# M0519AE_v1 register map
File version: 1.0
Registers are 32-bit, read-write, reset 0x0 unless marked. A register's access mark holds for its fields unless they carry their own. Offsets are from the block's base; [hi:lo] are bit positions; {n}, {i} and the like mark numbered series; 'fields as' and 'values as' point back to an identical list.

## EADC — EADC Register Map
Base 0x400E0000
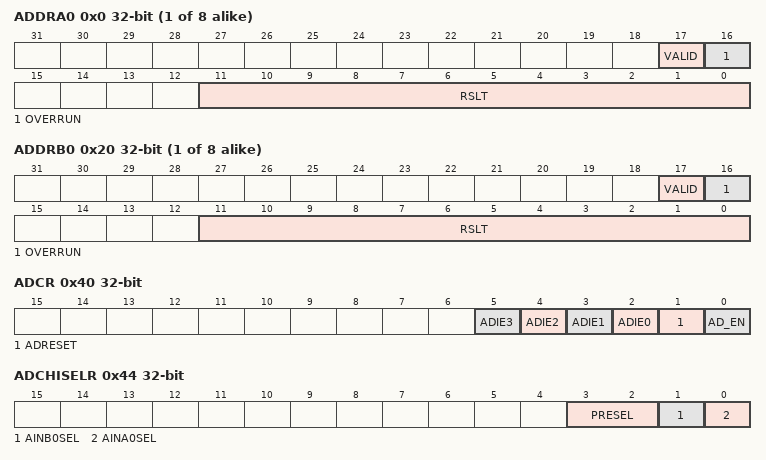
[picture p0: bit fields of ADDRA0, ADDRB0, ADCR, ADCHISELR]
{0x0+4i} ADDRA{i} ro (i=0..7) — A/D Data Register {i} for SAMPLEA{i}
  [17] VALID — Valid Flag. This bit is set to 1 when corresponding SAMPLE channel analog input conversion is completed and cleared by hardware after ADDR register is read.
    0=Data in RSLT[11:0] bits is not valid; 1=Data in RSLT[11:0] bits is valid
  [16] OVERRUN — over Run Flag
    0=Data in RSLT[11:0] is the recent conversion result; 1=Data in RSLT[11:0] is overwritten. If converted data in RSLT[11:0] has not been read before new conversion result is loaded to this register, OVERRUN is set to 1. It is cleared by hardware after ADDR register is read
  [11:0] RSLT — A/D Conversion Result. This field contains 12-bit conversion result.
{0x20+4i} ADDRB{i} ro (i=0..7) — A/D Data Register {i+8} for SAMPLEB{i}
  fields as ADDRA0
0x40 ADCR — A/D Control Register
  [n+2] ADIE{n} (n=0..3) — Specific SAMPLE A/D ADINT{n} Interrupt Enable Bit. The A/D converter generates a conversion end ADF{n} flag in ADSR1 register upon the end of specific SAMPLE A/D conversion. If ADIE{n} bit is set then conversion end interrupt request ADINT{n} is generated.
    0=Specific SAMPLE A/D ADINT{n} interrupt function Disabled; 1=Specific SAMPLE A/D ADINT{n} interrupt function Enabled
  [1] ADRESET — ADCA, ADCB A/D Converter Control Circuits Reset. Note: This bit remains 1 during ADC reset, when ADC reset end, the ADRESET bit is automatically cleared to 0.
    0=Writing 0 has no effect; 1=Writing 1 will cause ADC control circuits reset to initial state, but not change the ADC registers value
  [0] AD_EN — A/D Converter Enable Bit. Note: Before starting the A/D conversion function, this bit should be set to 1. Clear it to 0 to disable A/D converter analog circuit power consumption.
    0=A/D converter Disabled; 1=A/D converter Enabled
0x44 ADCHISELR — A/D Channel Input Sources Select Register
  [3:2] PRESEL — A/D Channel AINA[7] Analog Input Selection
    0=Analog Input Channel AINA7; 1=Band-gap (VBG) Analog Input; 2=VTEMP Internal Temperature Sensor Analog Input; 3=Analog ground
  [1] AINB0SEL — A/D Channel AINB[0] Analog Input Selection
    0=AINB[0] pin P7.0E/EADC1_CH0 is selected as the A/D AINB[0] input signal; 1=OP Amplifier 1 output is selected as the A/D AINB[0] input signal
  [0] AINA0SEL — A/D Channel AINA[0] Analog Input Selection
    0=AINA[0] pin P6.0/EADC0_CH0is selected as the ADC AINA[0] input signal; 1=OP Amplifier 0 output is selected as the ADC AINA[0] input signal
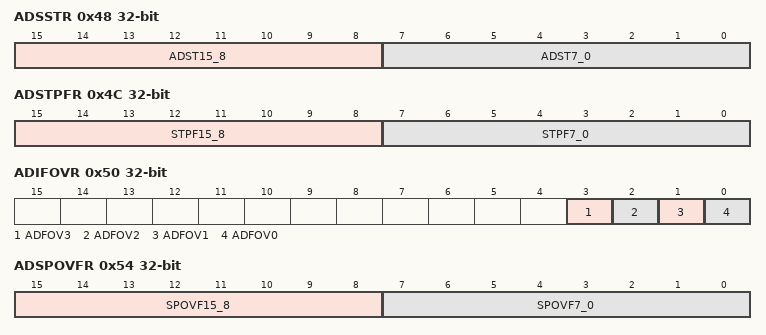
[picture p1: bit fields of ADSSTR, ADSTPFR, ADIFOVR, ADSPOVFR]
0x48 ADSSTR wo — A/D SAMPLE Software Start Register
  [15:8] ADST15_8 — A/D SAMPLEB7~0 Software Force to Start ADC Conversion Register
    0=No effect; 1=Cause an ADC conversion when the priority is given to SAMPLEB
  [7:0] ADST7_0 — A/D SAMPLEA7~0 Software Force to Start ADC Conversion Register
    0=No effect; 1=Cause an ADC conversion when the priority is given to SAMPLEA
0x4C ADSTPFR ro — A/D SAMPLE Start of Conversion Pending Flag Register
  [15:8] STPF15_8 — A/D SAMPLEB7~0 Start Conversion Pending Flag
    0=No pending conversion for SAMPLEB; 1=SAMPLEBn ADC start of conversion is pending
  [7:0] STPF7_0 — A/D SAMPLEA7~0 Start Conversion Pending Flag
    0=There is no pending conversion for SAMPLEA; 1=SAMPLEAn ADC start of conversion is pending
0x50 ADIFOVR — A/D ADINT3~0 Interrupt Flag over Run Register
  [3] ADFOV3 — A/D ADINT3 Interrupt Flag over Run Bit. Note: This bit is cleared by writing 1 to 1.
    0=ADINT3 interrupt flag is not over run; 1=ADINT3 interrupt pulse received when ADF3 is 1
  [2] ADFOV2 — A/D ADINT2 Interrupt Flag over Run Bit. Note: This bit is cleared by writing 1 to 1.
    0=ADINT2 interrupt flag is not over run; 1=ADINT2 interrupt flag is overwrite to 1
  [1] ADFOV1 — A/D ADINT1 Interrupt Flag over Run Bit. Note: This bit is cleared by writing 1 to 1.
    0=ADINT1 interrupt flag is not over run; 1=ADINT1 interrupt flag is overwrite to 1
  [0] ADFOV0 — A/D ADINT0 Interrupt Flag over Run Bit. Note: This bit is cleared by writing 1 to 1.
    0=ADINT0 interrupt flag is not over run; 1=ADINT0 interrupt flag is overwrite to 1
0x54 ADSPOVFR — A/D SAMPLE Start of Conversion over Run Flag Register
  [15:8] SPOVF15_8 — A/D SAMPLEB7~SAMPLEB0 Start Conversion Overrun Flag
    0=No SAMPLE event overrun; 1=Indicates new SAMPLEBn event is generated while an old one event is pending
  [7:0] SPOVF7_0 — A/D SAMPLEA7~SAMPLEA0 Start Conversion Overrun Flag
    0=No SAMPLE event overrun; 1=Indicates new SAMPLEAn event is generated while an old one event is pending
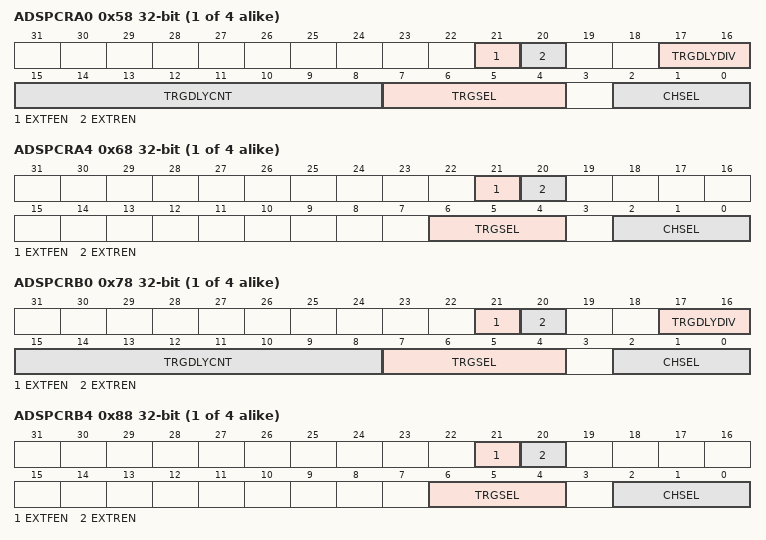
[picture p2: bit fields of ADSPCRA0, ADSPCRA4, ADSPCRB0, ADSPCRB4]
{0x58+4i} ADSPCRA{i} (i=0..3) — A/D SAMPLEA{i} Control Register
  [21] EXTFEN — A/D External Trigger Falling Edge Enable Bit
    0=Falling edge Disabled when A/D selects STADC as trigger source; 1=Falling edge Enabled when A/D selects STADC as trigger source
  [20] EXTREN — A/D External Trigger Rising Edge Enable Bit
    0=Rising edge Disabled when A/D selects STADC as trigger source; 1=Rising edge Enabled when A/D selects STADC as trigger source
  [17:16] TRGDLYDIV — A/D SAMPLE Start Conversion Trigger Delay Clock Divider Selection. Trigger delay clock frequency:
    0=ADC_CLK/1; 1=ADC_CLK/2; 2=ADC_CLK/4; 3=ADC_CLK/16
  [15:8] TRGDLYCNT — A/D SAMPLE Start Conversion Trigger Delay Time
  [7:4] TRGSEL — A/D SAMPLE Start Conversion Trigger Source Selection
    0=Disable hardware trigger; 1=External trigger from STADC pin input; 2=ADC ADINT0 interrupt EOC pulse trigger; 3=ADC ADINT1 interrupt EOC pulse trigger; {v}=Timer{v-4} overflow pulse trigger (v=4..7); 8=PWM00 trigger; 9=PWM02 trigger; 10=PWM04 trigger; 11=PWM10 trigger; 12=PWM12 trigger; 13=PWM14 trigger; 14=PWM20 trigger; 15=PWM21 trigger
  [2:0] CHSEL — A/D SAMPLEA,B Channel Selection
    {v}=AINx[{v}] (v=0..7)
{0x58+4i} ADSPCRA{i} (i=4..7) — A/D SAMPLEA{i} Control Register
  [21] EXTFEN — A/D External Trigger Falling Edge Enable Bit
    values as ADSPCRA0.EXTFEN
  [20] EXTREN — A/D External Trigger Rising Edge Enable Bit
    values as ADSPCRA0.EXTREN
  [6:4] TRGSEL — A/D SAMPLE Start Conversion Trigger Source Selection
    0=Disable hardware trigger; 1=External trigger from STADC pin input; 2=ADC ADINT0 interrupt EOC pulse trigger; 3=ADC ADINT1 interrupt EOC pulse trigger; {v}=Timer{v-4} overflow pulse trigger (v=4..7)
  [2:0] CHSEL — A/D SAMPLEA,B Channel Selection
    {v}=AINx[{v}] (v=0..7)
{0x78+4i} ADSPCRB{i} (i=0..3) — A/D SAMPLEB{i} Control Register
  fields as ADSPCRA0
{0x78+4i} ADSPCRB{i} (i=4..7) — A/D SAMPLEB{i} Control Register
  fields as ADSPCRA4
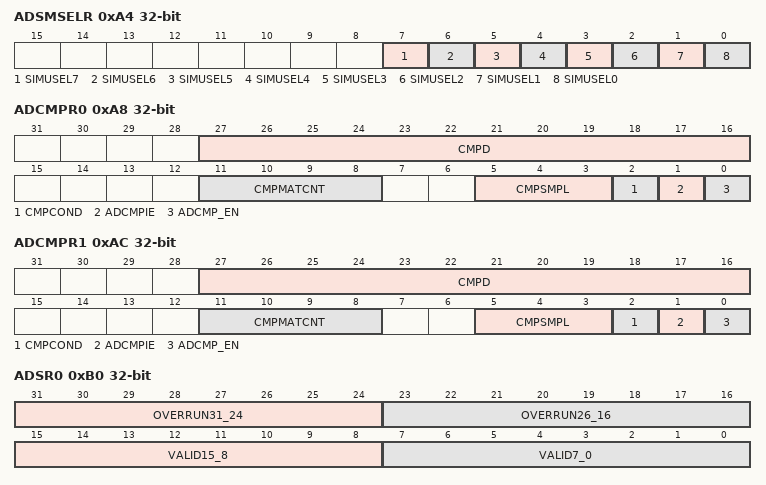
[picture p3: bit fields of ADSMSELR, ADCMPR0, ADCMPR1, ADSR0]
0xA4 ADSMSELR — A/D SAMPLE Simultaneous Mode Select Register
  [7] SIMUSEL7 — A/D SAMPLEA7, SAMPLEB7 Simultaneous Sampling Mode Selection
    0=SAMPLEA7, SAMPLEB7 are in single sampling mode, both SAMPLEA7 and SAMPLEB7's 3 bits of CHSEL define the ADC channels to be converted; 1=SAMPLEA7, SAMPLEB7 are in simultaneous sampling mode, Only SAMPLEA7 can trigger both the ADC conversions of SAMPLEA7 and SAMPLEB7, SAMPLEB7 trigger select TRGSEL is ignored. If SAMPLEA7's CHSEL = 1, SAMPLEB7's CHSEL = 3, the pair of channels are AINA[1], AINB[3], they will do the ADC conversion at the same time
  [6] SIMUSEL6 — A/D SAMPLEA6, SAMPLEB6 Simultaneous Sampling Mode Selection
    0=SAMPLEA6, SAMPLEB6 are in single sampling mode, both SAMPLEA6 and SAMPLEB6's 3 bits of CHSEL define the ADC channels to be converted; 1=SAMPLEA6, SAMPLEB6 are in simultaneous sampling mode, Only SAMPLEA6 can trigger both the ADC conversions of SAMPLEA6 and SAMPLEB6, SAMPLEB6 trigger select TRGSEL is ignored. If SAMPLEA6's CHSEL = 1, and SAMPLEB6's CHSEL = 3, the pair of channels are AINA[1], AINB[3], they will do the ADC conversion at the same time
  [5] SIMUSEL5 — A/D SAMPLEA5, SAMPLEB5 Simultaneous Sampling Mode Selection
    0=SAMPLEA5, SAMPLEB5 are in single sampling mode, both SAMPLEA5 and SAMPLEB5's 3 bits of CHSEL define the ADC channels to be converted; 1=SAMPLEA5, SAMPLEB5 are in simultaneous sampling mode, Only SAMPLEA5 can trigger both the ADC conversions of SAMPLEA5 and SAMPLEB5, SAMPLEB5 trigger select TRGSEL is ignored. If SAMPLEA5's CHSEL = 1, and SAMPLEB5's CHSEL = 3, the pair of channels are AINA[1], AINB[3], they will do the ADC conversion at the same time
  [4] SIMUSEL4 — A/D SAMPLEA4, SAMPLEB4 Simultaneous Sampling Mode Select Ion
    0=SAMPLEA4, SAMPLEB4 are in single sampling mode, both SAMPLEA4 and SAMPLEB4's 3 bits of CHSEL define the ADC channels to be converted; 1=SAMPLEA4, SAMPLEB4 are in simultaneous sampling mode, Only SAMPLEA4 can trigger both the ADC conversions of SAMPLEA4 and SAMPLEB4, SAMPLEB4 trigger select TRGSEL is ignored. If SAMPLEA4's CHSEL = 1, and SAMPLEB4's CHSEL = 3, the pair of channels are AINA[1], AINB[3], they will do the ADC conversion at the same time
  [3] SIMUSEL3 — A/D SAMPLEA3, SAMPLEB3 Simultaneous Sampling Mode Select Ion
    0=SAMPLEA3, SAMPLEB3 are in single sampling mode, both SAMPLEA3 and SAMPLEB3's 3 bits of CHSEL define the ADC channels to be converted; 1=SAMPLEA3, SAMPLEB3 are in simultaneous sampling mode, Only SAMPLEA3 can trigger both the ADC conversions of SAMPLEA3 and SAMPLEB3, SAMPLEB3 trigger select TRGSEL is ignored. If SAMPLEA3's CHSEL = 1, and SAMPLEB3's CHSEL = 3, the pair of channels are AINA[1], AINB[3], they will do the ADC conversion at the same time
  [2] SIMUSEL2 — A/D SAMPLEA2, SAMPLEB2 Simultaneous Sampling Mode Selection
    0=SAMPLEA2, SAMPLEB2 are in single sampling mode, both SAMPLEA2 and SAMPLEB2's 3 bits of CHSEL define the ADC channels to be converted; 1=SAMPLEA2, SAMPLEB2 are in simultaneous sampling mode, Only SAMPLEA2 can trigger both the ADC conversions of SAMPLEA2 and SAMPLEB2, SAMPLEB2 trigger select TRGSEL is ignored. If SAMPLEA2's CHSEL = 1, and SAMPLEB2's CHSEL = 3, the pair of channels are AINA[1], AINB[3], they will do the ADC conversion at the same time
  [1] SIMUSEL1 — A/D SAMPLEA1, SAMPLEB1 Simultaneous Sampling Mode Selection
    0=SAMPLEA1, SAMPLEB1 are in single sampling mode, both SAMPLEA1 and SAMPLEB1's 3 bits of CHSEL define the ADC channels to be converted; 1=SAMPLEA1, SAMPLEB1 are in simultaneous sampling mode, Only SAMPLEA1 can trigger both the ADC conversions of SAMPLEA1 and SAMPLEB1, SAMPLEB1 trigger select TRGSEL is ignored. If SAMPLEA1's CHSEL = 1, and SAMPLEB1's CHSEL = 3, the pair of channels are AINA[1], AINB[3], they will do the ADC conversion at the same time
  [0] SIMUSEL0 — A/D SAMPLEA0, SAMPLEB0 Simultaneous Sampling Mode Selection
    0=SAMPLEA0, SAMPLEB0 are in single sampling mode, both SAMPLEA0 and SAMPLEB0's 3 bits of CHSEL define the ADC channels to be converted; 1=SAMPLEA0, SAMPLEB0 are in simultaneous sampling mode, Only SAMPLEA0 can trigger both the ADC conversions of SAMPLEA0 and SAMPLEB0, SAMPLEB0 trigger select TRGSEL is ignored. If SAMPLEA0's CHSEL = 1, and SAMPLEB0's CHSEL = 3, the pair of channels are AINA[1], AINB[3], they will do the ADC conversion at the same time
0xA8 ADCMPR0 — A/D Result Compare Register 0
  [27:16] CMPD — Comparison Data. The 12 bits data is used to compare with the conversion result of specified SAMPLE. Software can use it to monitor the external analog input pin voltage transition without imposing a load on software.
  [11:8] CMPMATCNT — Compare Match Count
  [5:3] CMPSMPL — Compare SAMPLE Selection
    {v}=SAMPLEA{v} conversion result ADDRA{v} is selected to be compared (v=0..3); {v}=SAMPLEB{v-4} conversion result ADDRB{v-4} is selected to be compared (v=4..7)
  [2] CMPCOND — Compare Condition
    0=Set the compare condition as that when a 12-bit A/D conversion result is less than the 12-bit CMPD(ADCMPRn[27:16], n=0, 1), the internal match counter will increase one; 1=Set the compare condition as that when a 12-bit A/D conversion result is greater or equal to the 12-bit CMPD(ADCMPRn[27:16] , n=0, 1), the internal match counter will increase one
  [1] ADCMPIE — A/D Result Compare Interrupt Enable Bit
    0=Compare function interrupt Disabled; 1=Compare function interrupt Enabled
  [0] ADCMP_EN — A/D Result Compare Enable Bit
    0=Compare Disabled; 1=Compare Enabled
0xAC ADCMPR1 — A/D Result Compare Register 1
  fields as ADCMPR0
0xB0 ADSR0 ro — A/D Status Register 0
  [31:24] OVERRUN31_24 — ADDRB7~0 over Run Flag
  [23:16] OVERRUN26_16 — ADDRA7~0 over Run Flag
  [15:8] VALID15_8 — ADDRB7~0 Data Valid Flag
  [7:0] VALID7_0 — ADDRA7~0 Data Valid Flag
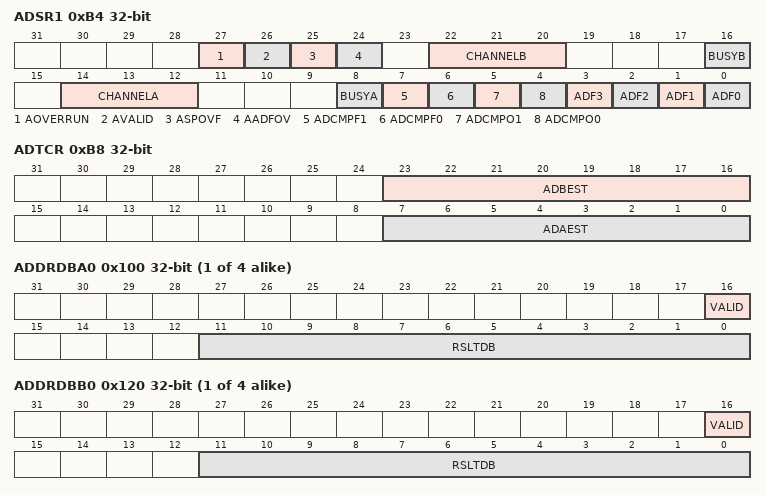
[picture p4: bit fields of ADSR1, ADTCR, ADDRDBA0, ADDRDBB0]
0xB4 ADSR1 — A/D Status Register 1
  [27] AOVERRUN — All SAMPLE A/D Result Data Register over Run Flags Check
    0=None of SAMPLE data register over run flag OVERRUNn is set to 1; 1=Any one of SAMPLE data register over run flag OVERRUNn is set to 1
  [26] AVALID — All SAMPLE A/D Result Data Register ADDR Data Valid Flag Check
    0=None of SAMPLE data register valid flag VALIDn is set to 1; 1=Any one of SAMPLE data register valid flag VALIDn is set to 1
  [25] ASPOVF — All A/D SAMPLE Start Conversion over Run Flags Check
    0=None of SAMPLE event over run flag SPOVFn is set to 1; 1=Any one of SAMPLE event over run flag SPOVFn is set to 1
  [24] AADFOV — All A/D Interrupt Flag over Run Bits Check
    0=None of ADINT interrupt flag ADFOVn is overwritten to 1; 1=Any one of ADINT interrupt flag ADFOVn is overwritten to 1
  [22:20] CHANNELB ro — Current Conversion Channel (Read Only)
    {v}=AINB[{v}] (v=0..7)
  [16] BUSYB ro — BUSY/IDLE (Read Only)
    0=A/D converter B (ADCB) is in idle state; 1=A/D converter B (ADCB) is busy at conversion
  [14:12] CHANNELA ro — Current Conversion Channel (Read Only)
    {v}=AINA[{v}] (v=0..7)
  [8] BUSYA ro — BUSY/IDLE (Read Only)
    0=A/D converter A (ADCA) is in idle state; 1=A/D converter A (ADCA) is busy at conversion
  [7] ADCMPF1 — ADC Compare 1 Flag. When the specific SAMPLE A/D conversion result meets setting condition in ADCMPR1 register then this bit is set to 1. And it is cleared by write 1.
    0=Conversion result in ADDR does not meet ADCMPR1 register setting; 1=Conversion result in ADDR meets ADCMPR1 register setting
  [6] ADCMPF0 — ADC Compare 0 Flag. When the specific SAMPLE A/D conversion result meets setting condition in ADCMPR0 then this bit is set to 1. And it is cleared by write 1.
    0=Conversion result in ADDR does not meet ADCMPR0 register setting; 1=Conversion result in ADDR meets ADCMPR0 register setting
  [5] ADCMPO1 — ADC Compare 1 Output Status Bit. The 12 bits compare1 data CMPD(ADCMPR1[27:16]) is used to compare with conversion result of specified SAMPLE. Software can use it to monitor the external analog input pin voltage status.
    0=Conversion result in ADDR less than CMPD(ADCMPR1[27:16]) setting; 1=Conversion result in ADDR great than or equal CMPD(ADCMPR1[27:16]) setting
  [4] ADCMPO0 — ADC Compare 0 Output Status Bit. The 12 bits compare0 data CMPD(ADCMPR0[27:16]) is used to compare with conversion result of specified SAMPLE. Software can use it to monitor the external analog input pin voltage status.
    0=Conversion result in ADDR is less than CMPD(ADCMPR0[27:16]) setting; 1=Conversion result in ADDR is great than or equal CMPD(ADCMPR0[27:16]) setting
  [3] ADF3 — A/D ADINT3 Interrupt Flag. Note1: It is cleared by writing 1. Note2: This bit indicates whether an A/D conversion of specific SAMPLE has been completed
    0=No ADINT3 interrupt pulse received; 1=ADINT3 interrupt pulse received
  [2] ADF2 — A/D ADINT2 Interrupt Flag. Note1: It is cleared by writing 1. Note2: This bit indicates whether an A/D conversion of specific SAMPLE has been completed.
    0=No ADINT2 interrupt pulse received; 1=ADINT2 interrupt pulse received
  [1] ADF1 — A/D ADINT1 Interrupt Flag. Note1: It is cleared by writing 1. Note2: This bit indicates whether an A/D conversion of specific SAMPLE has been completed.
    0=no ADINT1 interrupt pulse received; 1=ADINT1 interrupt pulse has been received
  [0] ADF0 — A/D ADINT0 Interrupt Flag. Note1: It is cleared by writing 1. Note2: This bit indicates whether an A/D conversion of specific SAMPLE has been completed.
    0=No ADINT0 interrupt pulse received; 1=ADINT0 interrupt pulse received
0xB8 ADTCR — A/D Timing Control Register
  [23:16] ADBEST — ADCB Extend Sampling Time. When A/D converting at high conversion rate, the sampling time of analog input voltage may not enough if input channel loading is heavy, User can extend A/D sampling time after trigger source is coming to get enough sampling time. The range of start delay time is from 0~255 ADC clock.
  [7:0] ADAEST — ADCA Extend Sampling Time. When A/D converting at high conversion rate, the sampling time of analog input voltage may not enough if input channel loading is heavy, User can extend A/D sampling time after trigger source is coming to get enough sampling time. The range of start delay time is from 0~255 ADC clock.
{0x100+4i} ADDRDBA{i} ro (i=0..3) — A/D Data Register Double Buffer for SAMPLEA{i}
  [16] VALID — Valid Flag
    0=Double data in RSLTDB[11:0] bits is not valid; 1=Double data in RSLTDB[11:0] bits is valid
  [11:0] RSLTDB — A/D Conversion Result
{0x120+4i} ADDRDBB{i} ro (i=0..3) — A/D Data Register Double Buffer for SAMPLEB{i}
  fields as ADDRDBA0
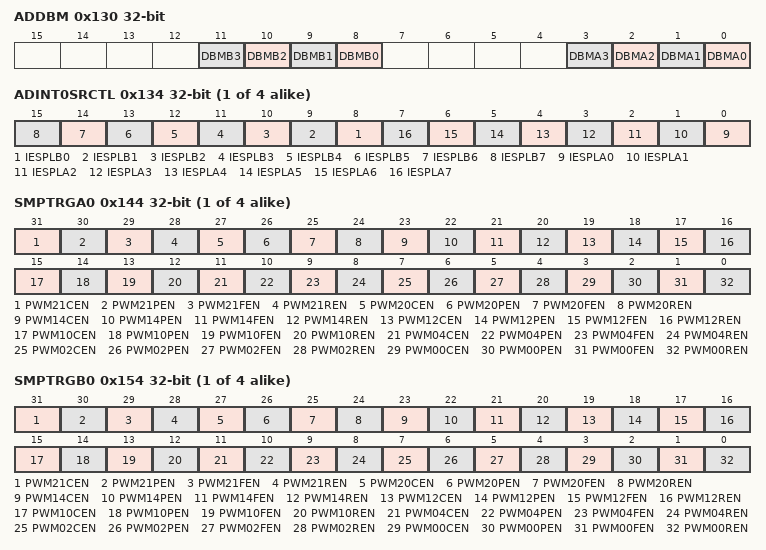
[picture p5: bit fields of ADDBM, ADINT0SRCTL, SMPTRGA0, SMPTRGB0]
0x130 ADDBM — A/D Double Buffer Mode Select
  [n+8] DBMB{n} (n=0..3) — Double Buffer Mode for SAMPLE B{n}
    0=SampleB{n} has one sample result register. (default); 1=SampleB{n} has two sample result registers
  [n] DBMA{n} (n=0..3) — Double Buffer Mode for SAMPLE A{n}
    0=SampleA{n} has one sample result register. (default); 1=SampleA{n} has two sample result registers
{0x134+4i} ADINT{i}SRCTL (i=0..3) — A/D Interrupt {i} Source Enable Control Register.
  [n+8] IESPLB{n} (n=0..7) — SAMPLE B{n} Interrupt Mask Enable Bit
    0=SAMPLE B{n} interrupt mask Disabled; 1=SAMPLE B{n} interrupt mask Enabled
  [n] IESPLA{n} (n=0..7) — SAMPLE A{n} Interrupt Mask Enable Bit
    0=SAMPLE A{n} interrupt mask Disabled; 1=SAMPLE A{n} interrupt mask Enabled
{0x144+4i} SMPTRGA{i} (i=0..3) — A/D Trigger Condition for SAMPLEA{i}
  [31] PWM21CEN — BPWM0_CH1 Center Trigger Enable Bit
    0=BPWM0_CH1 center trigger Disabled; 1=BPWM0_CH1 center trigger Enabled
  [30] PWM21PEN — BPWM0_CH1 Period Trigger Enable Bit
    0=BPWM0_CH1 period trigger Disabled; 1=BPWM0_CH1 period trigger Enabled
  [29] PWM21FEN — BPWM0_CH1 Falling Edge Trigger Enable Bit
    0=BPWM0_CH1 falling edge trigger Disabled; 1=BPWM0_CH1 falling edge trigger Enabled
  [28] PWM21REN — BPWM0_CH1 Rising Edge Trigger Enable Bit
    0=BPWM0_CH1 rising edge trigger Disabled; 1=BPWM0_CH1 rising edge trigger Enabled
  [27] PWM20CEN — BPWM0_CH0 Center Trigger Enable Bit
    0=BPWM0_CH0 center trigger Disabled; 1=BPWM0_CH0 center trigger Enabled
  [26] PWM20PEN — BPWM0_CH0 Period Trigger Enable Bit
    0=BPWM0_CH0 period trigger Disabled; 1=BPWM0_CH0 period trigger Enabled
  [25] PWM20FEN — BPWM0_CH0 Falling Edge Trigger Enable Bit
    0=BPWM0_CH0 falling edge trigger Disabled; 1=BPWM0_CH0 falling edge trigger Enabled
  [24] PWM20REN — BPWM0_CH0 Rising Edge Trigger Enable Bit
    0=BPWM0_CH0 rising edge trigger Disabled; 1=BPWM0_CH0 rising edge trigger Enabled
  [23] PWM14CEN — PWM1_CH4 Center Trigger Enable Bit
    0=PWM1_CH4 center trigger Disabled; 1=PWM1_CH4 center trigger Enabled
  [22] PWM14PEN — PWM1_CH4 Period Trigger Enable Bit
    0=PWM1_CH4 period trigger Disabled; 1=PWM1_CH4 period trigger Enabled
  [21] PWM14FEN — PWM1_CH4 Falling Edge Trigger Enable Bit
    0=PWM1_CH4 falling edge trigger Disabled; 1=PWM1_CH4 falling edge trigger Enabled
  [20] PWM14REN — PWM1_CH4 Rising Edge Trigger Enable Bit
    0=PWM1_CH4 rising edge trigger Disabled; 1=PWM1_CH4 rising edge trigger Enabled
  [19] PWM12CEN — PWM1_CH2 Center Trigger Enable Bit
    0=PWM1_CH2 center trigger Disabled; 1=PWM1_CH2 center trigger Enabled
  [18] PWM12PEN — PWM1_CH2 Period Trigger Enable Bit
    0=PWM1_CH2 period trigger Disabled; 1=PWM1_CH2 period trigger Enabled
  [17] PWM12FEN — PWM1_CH2 Falling Edge Trigger Enable Bit
    0=PWM1_CH2 falling edge trigger Disabled; 1=PWM1_CH2 falling edge trigger Enabled
  [16] PWM12REN — PWM1_CH2 Rising Edge Trigger Enable Bit
    0=PWM1_CH2 rising edge trigger Disabled; 1=PWM1_CH2 rising edge trigger Enabled
  [15] PWM10CEN — PWM1_CH0 Center Trigger Enable Bit
    0=PWM1_CH0 center trigger Disabled; 1=PWM1_CH0 center trigger Enabled
  [14] PWM10PEN — PWM1_CH0 Period Trigger Enable Bit
    0=PWM1_CH0 period trigger Disabled; 1=PWM1_CH0 period trigger Enabled
  [13] PWM10FEN — PWM1_CH0 Falling Edge Trigger Enable Bit
    0=PWM1_CH0 falling edge trigger Disabled; 1=PWM1_CH0 falling edge trigger Enabled
  [12] PWM10REN — PWM1_CH0 Rising Edge Trigger Enable Bit
    0=PWM1_CH0 rising edge trigger Disabled; 1=PWM1_CH0 rising edge trigger Enabled
  [11] PWM04CEN — PWM0_CH4 Center Trigger Enable Bit
    0=PWM0_CH4 center trigger Disabled; 1=PWM0_CH4 center trigger Enabled
  [10] PWM04PEN — PWM0_CH4 Period Trigger Enable Bit
    0=PWM0_CH4 period trigger Disabled; 1=PWM0_CH4 period trigger Enabled
  [9] PWM04FEN — PWM0_CH4 Falling Rdge Trigger Enable Bit
    0=PWM0_CH4 falling edge trigger Disabled; 1=PWM0_CH4 falling edge trigger Enabled
  [8] PWM04REN — PWM0_CH4 Rising Edge Trigger Enable Bit
    0=PWM0_CH4 rising edge trigger Disabled; 1=PWM0_CH4 rising edge trigger Enabled
  [7] PWM02CEN — PWM0_CH2 Center Trigger Enable Bit
    0=PWM0_CH2 center trigger Disabled; 1=PWM0_CH2 center trigger Enabled
  [6] PWM02PEN — PWM0_CH2 Period Trigger Enable Bit
    0=PWM0_CH2 period trigger Disabled; 1=PWM0_CH2 period trigger Enabled
  [5] PWM02FEN — PWM0_CH2 Falling Edge Trigger Enable Bit
    0=PWM0_CH2 falling edge trigger Disabled; 1=PWM0_CH2 falling edge trigger Enabled
  [4] PWM02REN — PWM0_CH2 Rising Edge Trigger Enable Bit
    0=PWM0_CH2 rising edge trigger Disabled; 1=PWM0_CH2 rising edge trigger Enabled
  [3] PWM00CEN — PWM0_CH0 Center Trigger Enable Bit
    0=PWM0_CH0 center trigger Disabled; 1=PWM0_CH0 center trigger Enabled
  [2] PWM00PEN — PWM0_CH0 Period Trigger Enable Bit
    0=PWM0_CH0 period trigger Disabled; 1=PWM0_CH0 period trigger Enabled
  [1] PWM00FEN — PWM0_CH0 Falling Edge Trigger Enable Bit
    0=PWM0_CH0 falling edge trigger Disabled; 1=PWM0_CH0 falling edge trigger Enabled
  [0] PWM00REN — PWM0_CH0 Rising Edge Trigger Enable Bit
    0=PWM0_CH0 rising edge trigger Disabled; 1=PWM0_CH0 rising edge trigger Enabled
{0x154+4i} SMPTRGB{i} (i=0..3) — A/D Trigger Condition for SAMPLEB{i}
  fields as SMPTRGA0
